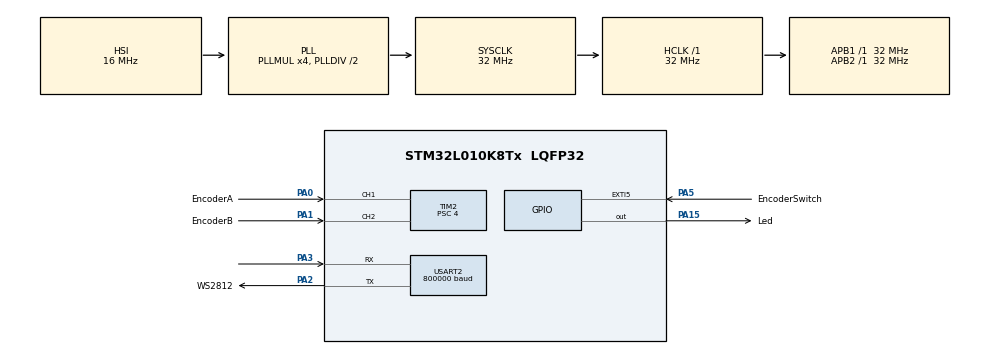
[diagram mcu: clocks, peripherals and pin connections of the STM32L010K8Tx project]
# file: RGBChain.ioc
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Mcu.Family=STM32L0
Mcu.Name=STM32L010K8Tx
Mcu.Package=LQFP32
NVIC.EXTI4_15_IRQn=true\:0\:0\:false\:false\:true\:true\:true
PA0.GPIO_Label=EncoderA
PA0.GPIO_PuPd=GPIO_PULLUP
PA0.GPIO_Speed=GPIO_SPEED_FREQ_HIGH
PA0.Signal=S_TIM2_CH1
PA1.GPIO_Label=EncoderB
PA1.GPIO_PuPd=GPIO_PULLUP
PA1.GPIO_Speed=GPIO_SPEED_FREQ_HIGH
PA1.Signal=S_TIM2_CH2
PA13.Mode=Serial_Wire
PA13.Signal=SYS_SWDIO
PA14.Mode=Serial_Wire
PA14.Signal=SYS_SWCLK
PA15.GPIO_Label=Led
PA15.Signal=GPIO_Output
PA2.GPIO_Label=WS2812
PA2.Mode=Asynchronous
PA2.Signal=USART2_TX
PA3.Mode=Asynchronous
PA3.Signal=USART2_RX
PA5.GPIO_Label=EncoderSwitch
PA5.GPIO_ModeDefaultEXTI=GPIO_MODE_IT_FALLING
PA5.Signal=GPXTI5
ProjectManager.HeapSize=0x200
ProjectManager.StackSize=0x400
ProjectManager.TargetToolchain=STM32CubeIDE
RCC.ADCFreq_Value=16000000
RCC.AHBFreq_Value=32000000
RCC.APB1Freq_Value=32000000
RCC.APB1TimFreq_Value=32000000
RCC.APB2Freq_Value=32000000
RCC.APB2TimFreq_Value=32000000
RCC.HCLKFreq_Value=32000000
RCC.HSI16_VALUE=16000000
RCC.HSI_VALUE=16000000
RCC.LSE_VALUE=32768
RCC.MSI_VALUE=2097000
RCC.PLLMUL=RCC_PLLMUL_4
RCC.SYSCLKFreq_VALUE=32000000
RCC.SYSCLKSource=RCC_SYSCLKSOURCE_PLLCLK
RCC.VCOOutputFreq_Value=64000000
SH.S_TIM2_CH1.0=TIM2_CH1,Encoder_Interface
SH.S_TIM2_CH2.0=TIM2_CH2,Encoder_Interface
TIM2.AutoReloadPreload=TIM_AUTORELOAD_PRELOAD_ENABLE
TIM2.EncoderMode=TIM_ENCODERMODE_TI12
TIM2.IC1Filter=10
TIM2.IC1Polarity=TIM_ICPOLARITY_FALLING
TIM2.IC2Filter=10
TIM2.IC2Polarity=TIM_ICPOLARITY_FALLING
TIM2.Period=255
TIM2.Prescaler=4
USART2.BaudRate=800000
USART2.Mode=MODE_TX
USART2.VirtualMode-Asynchronous=VM_ASYNC
USART2.WordLength=WORDLENGTH_7B
board=custom

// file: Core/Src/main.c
/* USER CODE BEGIN Header */
/**
  ******************************************************************************
  * @file           : main.c
  * @brief          : Main program body
  ******************************************************************************
  * @attention
  *
  * <h2><center>&copy; Copyright (c) 2020 STMicroelectronics.
  * All rights reserved.</center></h2>
  *
  * This software component is licensed by ST under BSD 3-Clause license,
  * the "License"; You may not use this file except in compliance with the
  * License. You may obtain a copy of the License at:
  *                        opensource.org/licenses/BSD-3-Clause
  *
  ******************************************************************************
  */
/* USER CODE END Header */
#include "main.h"

/* USER CODE BEGIN Includes */
#include "RgbChain.hpp"
/* USER CODE END Includes */

TIM_HandleTypeDef htim2;

UART_HandleTypeDef huart2;

void SystemClock_Config(void);
static void MX_GPIO_Init(void);
static void MX_TIM2_Init(void);
static void MX_USART2_UART_Init(void);

int main(void)
{

  /* MCU Configuration--------------------------------------------------------*/

  /* Reset of all peripherals, Initializes the Flash interface and the Systick. */
  HAL_Init();

  /* Configure the system clock */
  SystemClock_Config();

  /* Initialize all configured peripherals */
  MX_GPIO_Init();
  MX_TIM2_Init();
  MX_USART2_UART_Init();
  /* USER CODE BEGIN 2 */

  RgbChain_Init();

  /* USER CODE END 2 */

  /* Infinite loop */
  /* USER CODE BEGIN WHILE */
  while (1)
  {
	RgbChain_Loop();

    /* USER CODE END WHILE */

  }
}

void SystemClock_Config(void)
{
  RCC_OscInitTypeDef RCC_OscInitStruct = {0};
  RCC_ClkInitTypeDef RCC_ClkInitStruct = {0};
  RCC_PeriphCLKInitTypeDef PeriphClkInit = {0};

  /** Configure the main internal regulator output voltage
  */
  __HAL_PWR_VOLTAGESCALING_CONFIG(PWR_REGULATOR_VOLTAGE_SCALE1);
  /** Initializes the RCC Oscillators according to the specified parameters
  * in the RCC_OscInitTypeDef structure.
  */
  RCC_OscInitStruct.OscillatorType = RCC_OSCILLATORTYPE_HSI;
  RCC_OscInitStruct.HSIState = RCC_HSI_ON;
  RCC_OscInitStruct.HSICalibrationValue = RCC_HSICALIBRATION_DEFAULT;
  RCC_OscInitStruct.PLL.PLLState = RCC_PLL_ON;
  RCC_OscInitStruct.PLL.PLLSource = RCC_PLLSOURCE_HSI;
  RCC_OscInitStruct.PLL.PLLMUL = RCC_PLLMUL_4;
  RCC_OscInitStruct.PLL.PLLDIV = RCC_PLLDIV_2;
  if (HAL_RCC_OscConfig(&RCC_OscInitStruct) != HAL_OK)
  {
    Error_Handler();
  }
  /** Initializes the CPU, AHB and APB buses clocks
  */
  RCC_ClkInitStruct.ClockType = RCC_CLOCKTYPE_HCLK|RCC_CLOCKTYPE_SYSCLK
                              |RCC_CLOCKTYPE_PCLK1|RCC_CLOCKTYPE_PCLK2;
  RCC_ClkInitStruct.SYSCLKSource = RCC_SYSCLKSOURCE_PLLCLK;
  RCC_ClkInitStruct.AHBCLKDivider = RCC_SYSCLK_DIV1;
  RCC_ClkInitStruct.APB1CLKDivider = RCC_HCLK_DIV1;
  RCC_ClkInitStruct.APB2CLKDivider = RCC_HCLK_DIV1;

  if (HAL_RCC_ClockConfig(&RCC_ClkInitStruct, FLASH_LATENCY_1) != HAL_OK)
  {
    Error_Handler();
  }
  PeriphClkInit.PeriphClockSelection = RCC_PERIPHCLK_USART2;
  PeriphClkInit.Usart2ClockSelection = RCC_USART2CLKSOURCE_PCLK1;
  if (HAL_RCCEx_PeriphCLKConfig(&PeriphClkInit) != HAL_OK)
  {
    Error_Handler();
  }
}

static void MX_TIM2_Init(void)
{

  TIM_Encoder_InitTypeDef sConfig = {0};
  TIM_MasterConfigTypeDef sMasterConfig = {0};

  htim2.Instance = TIM2;
  htim2.Init.Prescaler = 4;
  htim2.Init.CounterMode = TIM_COUNTERMODE_UP;
  htim2.Init.Period = 255;
  htim2.Init.ClockDivision = TIM_CLOCKDIVISION_DIV1;
  htim2.Init.AutoReloadPreload = TIM_AUTORELOAD_PRELOAD_ENABLE;
  sConfig.EncoderMode = TIM_ENCODERMODE_TI12;
  sConfig.IC1Polarity = TIM_ICPOLARITY_FALLING;
  sConfig.IC1Selection = TIM_ICSELECTION_DIRECTTI;
  sConfig.IC1Prescaler = TIM_ICPSC_DIV1;
  sConfig.IC1Filter = 10;
  sConfig.IC2Polarity = TIM_ICPOLARITY_FALLING;
  sConfig.IC2Selection = TIM_ICSELECTION_DIRECTTI;
  sConfig.IC2Prescaler = TIM_ICPSC_DIV1;
  sConfig.IC2Filter = 10;
  if (HAL_TIM_Encoder_Init(&htim2, &sConfig) != HAL_OK)
  {
    Error_Handler();
  }
  sMasterConfig.MasterOutputTrigger = TIM_TRGO_RESET;
  sMasterConfig.MasterSlaveMode = TIM_MASTERSLAVEMODE_DISABLE;
  if (HAL_TIMEx_MasterConfigSynchronization(&htim2, &sMasterConfig) != HAL_OK)
  {
    Error_Handler();
  }

}

static void MX_USART2_UART_Init(void)
{

  huart2.Instance = USART2;
  huart2.Init.BaudRate = 800000;
  huart2.Init.WordLength = UART_WORDLENGTH_7B;
  huart2.Init.StopBits = UART_STOPBITS_1;
  huart2.Init.Parity = UART_PARITY_NONE;
  huart2.Init.Mode = UART_MODE_TX;
  huart2.Init.HwFlowCtl = UART_HWCONTROL_NONE;
  huart2.Init.OverSampling = UART_OVERSAMPLING_16;
  huart2.Init.OneBitSampling = UART_ONE_BIT_SAMPLE_DISABLE;
  huart2.AdvancedInit.AdvFeatureInit = UART_ADVFEATURE_NO_INIT;
  if (HAL_UART_Init(&huart2) != HAL_OK)
  {
    Error_Handler();
  }

}

static void MX_GPIO_Init(void)
{
  GPIO_InitTypeDef GPIO_InitStruct = {0};

  /* GPIO Ports Clock Enable */
  __HAL_RCC_GPIOA_CLK_ENABLE();

  /*Configure GPIO pin Output Level */
  HAL_GPIO_WritePin(Led_GPIO_Port, Led_Pin, GPIO_PIN_RESET);

  /*Configure GPIO pin : EncoderSwitch_Pin */
  GPIO_InitStruct.Pin = EncoderSwitch_Pin;
  GPIO_InitStruct.Mode = GPIO_MODE_IT_FALLING;
  GPIO_InitStruct.Pull = GPIO_NOPULL;
  HAL_GPIO_Init(EncoderSwitch_GPIO_Port, &GPIO_InitStruct);

  /*Configure GPIO pin : Led_Pin */
  GPIO_InitStruct.Pin = Led_Pin;
  GPIO_InitStruct.Mode = GPIO_MODE_OUTPUT_PP;
  GPIO_InitStruct.Pull = GPIO_NOPULL;
  GPIO_InitStruct.Speed = GPIO_SPEED_FREQ_LOW;
  HAL_GPIO_Init(Led_GPIO_Port, &GPIO_InitStruct);

  /* EXTI interrupt init*/
  HAL_NVIC_SetPriority(EXTI4_15_IRQn, 0, 0);
  HAL_NVIC_EnableIRQ(EXTI4_15_IRQn);

}

void Error_Handler(void)
{
  /* USER CODE BEGIN Error_Handler_Debug */
  /* User can add his own implementation to report the HAL error return state */
	while (1)
	{
		HAL_GPIO_TogglePin(Led_GPIO_Port, Led_Pin);
		HAL_Delay(50);
	}
  /* USER CODE END Error_Handler_Debug */
}

/************************ (C) COPYRIGHT STMicroelectronics *****END OF FILE****/
